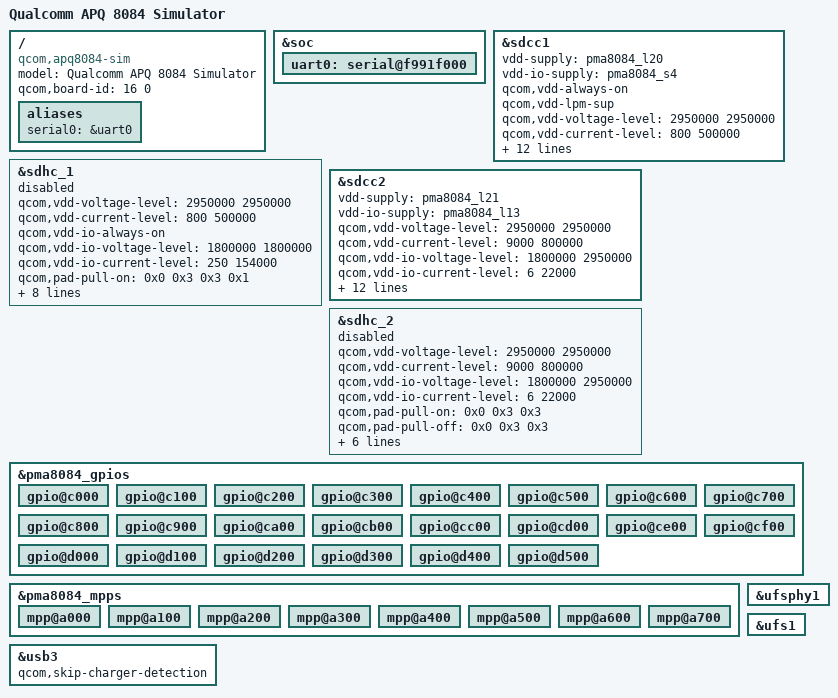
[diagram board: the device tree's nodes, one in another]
/* Copyright (c) 2013, The Linux Foundation. All rights reserved.
 *
 * This program is free software; you can redistribute it and/or modify
 * it under the terms of the GNU General Public License version 2 and
 * only version 2 as published by the Free Software Foundation.
 *
 * This program is distributed in the hope that it will be useful,
 * but WITHOUT ANY WARRANTY; without even the implied warranty of
 * MERCHANTABILITY or FITNESS FOR A PARTICULAR PURPOSE.  See the
 * GNU General Public License for more details.
 */

/dts-v1/;

/include/ "apq8084.dtsi"

/ {
	model = "Qualcomm APQ 8084 Simulator";
	compatible = "qcom,apq8084-sim", "qcom,apq8084", "qcom,sim";
	qcom,board-id = <16 0>;

	aliases {
		serial0 = &uart0;
	};
};

&soc {
	uart0: serial@f991f000 {
		status = "ok";
	};
};

&sdcc1 {
	vdd-supply = <&pma8084_l20>;
	vdd-io-supply = <&pma8084_s4>;

	qcom,vdd-always-on;
	qcom,vdd-lpm-sup;
	qcom,vdd-voltage-level = <2950000 2950000>;
	qcom,vdd-current-level = <800 500000>;

	qcom,vdd-io-always-on;
	qcom,vdd-io-voltage-level = <1800000 1800000>;
	qcom,vdd-io-current-level = <250 154000>;

	qcom,pad-pull-on = <0x0 0x3 0x3>; /* no-pull, pull-up, pull-up */
	qcom,pad-pull-off = <0x0 0x3 0x3>; /* no-pull, pull-up, pull-up */
	qcom,pad-drv-on = <0x7 0x4 0x4>; /* 16mA, 10mA, 10mA */
	qcom,pad-drv-off = <0x0 0x0 0x0>; /* 2mA, 2mA, 2mA */

	qcom,clk-rates = <400000 20000000 25000000 50000000 100000000 200000000>;
	qcom,sup-voltages = <2950 2950>;
	qcom,nonremovable;
	qcom,bus-speed-mode = "HS200_1p8v", "DDR_1p8v";
	status = "ok";
};

&sdhc_1 {
	qcom,vdd-voltage-level = <2950000 2950000>;
	qcom,vdd-current-level = <800 500000>;

	qcom,vdd-io-always-on;
	qcom,vdd-io-voltage-level = <1800000 1800000>;
	qcom,vdd-io-current-level = <250 154000>;

	qcom,pad-pull-on = <0x0 0x3 0x3 0x1>; /* no-pull, pull-up, pull-up, pull-down */
	qcom,pad-pull-off = <0x0 0x3 0x3 0x1>; /* no-pull, pull-up, pull-up, pull-down */
	qcom,pad-drv-on = <0x7 0x4 0x4>; /* 16mA, 10mA, 10mA */
	qcom,pad-drv-off = <0x0 0x0 0x0>; /* 2mA, 2mA, 2mA */

	qcom,clk-rates = <400000 20000000 25000000 50000000 100000000 200000000 400000000>;
	qcom,nonremovable;
	qcom,bus-speed-mode = "HS400_1p8v", "HS200_1p8v", "DDR_1p8v";
	status = "disabled";
};

&sdcc2 {
	vdd-supply = <&pma8084_l21>;
	vdd-io-supply = <&pma8084_l13>;

	qcom,vdd-voltage-level = <2950000 2950000>;
	qcom,vdd-current-level = <9000 800000>;
	qcom,vdd-io-voltage-level = <1800000 2950000>;
	qcom,vdd-io-current-level = <6 22000>;
	qcom,vdd-io-lpm-sup;

	qcom,pad-pull-on = <0x0 0x3 0x3>; /* no-pull, pull-up, pull-up */
	qcom,pad-pull-off = <0x0 0x3 0x3>; /* no-pull, pull-up, pull-up */
	qcom,pad-drv-on = <0x7 0x4 0x4>; /* 16mA, 10mA, 10mA */
	qcom,pad-drv-off = <0x0 0x0 0x0>; /* 2mA, 2mA, 2mA */

	qcom,clk-rates = <400000 20000000 25000000 50000000 100000000 200000000>;
	qcom,sup-voltages = <2950 2950>;
	qcom,xpc;
	qcom,bus-speed-mode = "SDR12", "SDR25", "SDR50", "DDR50", "SDR104";
	qcom,current-limit = <800>;
	status = "ok";
};

&sdhc_2 {
	qcom,vdd-voltage-level = <2950000 2950000>;
	qcom,vdd-current-level = <9000 800000>;

	qcom,vdd-io-voltage-level = <1800000 2950000>;
	qcom,vdd-io-current-level = <6 22000>;

	qcom,pad-pull-on = <0x0 0x3 0x3>; /* no-pull, pull-up, pull-up */
	qcom,pad-pull-off = <0x0 0x3 0x3>; /* no-pull, pull-up, pull-up */
	qcom,pad-drv-on = <0x7 0x4 0x4>; /* 16mA, 10mA, 10mA */
	qcom,pad-drv-off = <0x0 0x0 0x0>; /* 2mA, 2mA, 2mA */

	qcom,clk-rates = <400000 20000000 25000000 50000000 100000000 200000000>;
	qcom,bus-speed-mode = "SDR12", "SDR25", "SDR50", "DDR50", "SDR104";
	status = "disabled";
};

&pma8084_gpios {
	gpio@c000 { /* GPIO 1 */
	};

	gpio@c100 { /* GPIO 2 */
	};

	gpio@c200 { /* GPIO 3 */
	};

	gpio@c300 { /* GPIO 4 */
	};

	gpio@c400 { /* GPIO 5 */
	};

	gpio@c500 { /* GPIO 6 */
	};

	gpio@c600 { /* GPIO 7 */
	};

	gpio@c700 { /* GPIO 8 */
	};

	gpio@c800 { /* GPIO 9 */
	};

	gpio@c900 { /* GPIO 10 */
	};

	gpio@ca00 { /* GPIO 11 */
	};

	gpio@cb00 { /* GPIO 12 */
	};

	gpio@cc00 { /* GPIO 13 */
	};

	gpio@cd00 { /* GPIO 14 */
	};

	gpio@ce00 { /* GPIO 15 */
	};

	gpio@cf00 { /* GPIO 16 */
	};

	gpio@d000 { /* GPIO 17 */
	};

	gpio@d100 { /* GPIO 18 */
	};

	gpio@d200 { /* GPIO 19 */
	};

	gpio@d300 { /* GPIO 20 */
	};

	gpio@d400 { /* GPIO 21 */
	};

	gpio@d500 { /* GPIO 22 */
	};
};

&pma8084_mpps {
	mpp@a000 { /* MPP 1 */
	};

	mpp@a100 { /* MPP 2 */
	};

	mpp@a200 { /* MPP 3 */
	};

	mpp@a300 { /* MPP 4 */
	};

	mpp@a400 { /* MPP 5 */
	};

	mpp@a500 { /* MPP 6 */
	};

	mpp@a600 { /* MPP 7 */
	};

	mpp@a700 { /* MPP 8 */
	};
};

&usb3 {
	qcom,skip-charger-detection;
};

&ufsphy1 {
	status = "ok";
};

&ufs1 {
	status = "ok";
};
